VERSION ""

NS_ :

BS_:

BU_: FS Inverter BMS

BO_ 1317 IVT_Msg_Result_T: 8 Vector__XXX
 SG_ IVT_Result_T : 16|32@1- (1,0) [-2147483648|2147483647] "°C" Vector__XXX

BO_ 1313 IVT_Msg_Result_I: 8 Vector__XXX
 SG_ IVT_Result_I : 16|32@1- (0.001,0) [-2147483.648|2147483.647] "A" Vector__XXX

BO_ 1318 IVT_Msg_Result_W: 8 Vector__XXX
 SG_ IVT_Result_W : 16|32@1- (1,0) [-2147483648|2147483647] "W" Vector__XXX

BO_ 1316 IVT_Msg_Result_U3: 8 Vector__XXX
 SG_ IVT_Result_U3 : 16|32@1- (0.001,0) [-2147483.648|2147483.647] "V" Vector__XXX

BO_ 1315 IVT_Msg_Result_U2: 8 Vector__XXX
 SG_ IVT_Result_U2 : 16|32@1- (0.001,0) [-2147483.648|2147483.647] "V" Vector__XXX

BO_ 1314 IVT_Msg_Result_U1: 8 Vector__XXX
 SG_ IVT_Result_U1 : 16|32@1- (0.001,0) [-2147483.648|2147483.647] "V" Vector__XXX

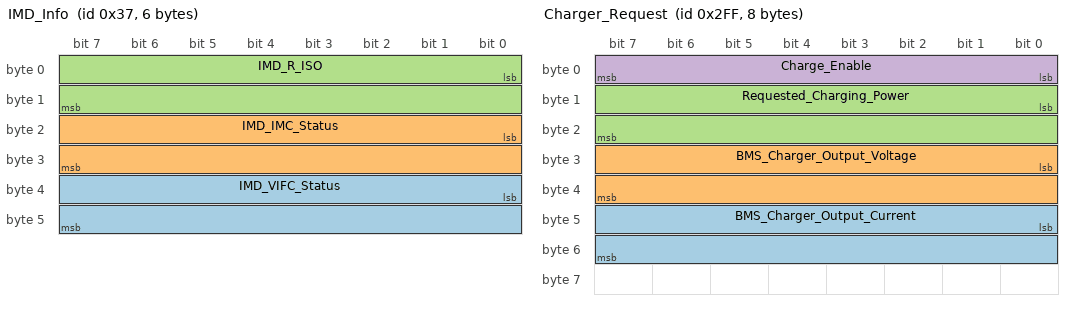
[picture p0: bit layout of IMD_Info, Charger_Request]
BO_ 55 IMD_Info: 6 Vector__XXX
 SG_ IMD_VIFC_Status : 32|16@1- (1,0) [0|0] "" Vector__XXX
 SG_ IMD_IMC_Status : 16|16@1- (1,0) [0|0] "" Vector__XXX
 SG_ IMD_R_ISO : 0|16@1- (1,0) [-32768|32767] "" Vector__XXX

BO_ 767 Charger_Request: 8 Vector__XXX
 SG_ BMS_Charger_Output_Current : 40|16@1+ (0.1,0) [0|6553.5] "A" Vector__XXX
 SG_ BMS_Charger_Output_Voltage : 24|16@1+ (0.1,0) [0|6553.5] "V" Vector__XXX
 SG_ Requested_Charging_Power : 8|16@1- (1,0) [-32768|32767] "" Vector__XXX
 SG_ Charge_Enable : 0|8@1- (1,0) [-128|127] "" Vector__XXX

BO_ 595 BMS_AvailCurrent: 8 Vector__XXX
 SG_ MaxDischarge : 16|16@1+ (0.1,0) [0|6553.5] "A" Vector__XXX
 SG_ MaxCharge : 0|16@1+ (0.1,0) [0|6553.5] "A" Vector__XXX

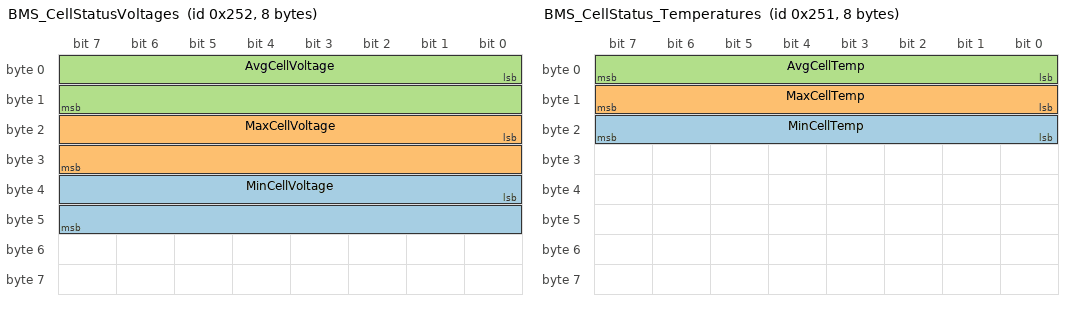
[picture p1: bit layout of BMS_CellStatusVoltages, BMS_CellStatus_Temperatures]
BO_ 594 BMS_CellStatusVoltages: 8 Vector__XXX
 SG_ MinCellVoltage : 32|16@1+ (0.1,0) [0|6553.5] "mV" Vector__XXX
 SG_ MaxCellVoltage : 16|16@1+ (0.1,0) [0|6553.5] "mV" Vector__XXX
 SG_ AvgCellVoltage : 0|16@1+ (0.1,0) [0|6553.5] "mV" Vector__XXX

BO_ 593 BMS_CellStatus_Temperatures: 8 Vector__XXX
 SG_ MinCellTemp : 16|8@1- (1,0) [-128|127] "degC" Vector__XXX
 SG_ MaxCellTemp : 8|8@1- (1,0) [-128|127] "degC" Vector__XXX
 SG_ AvgCellTemp : 0|8@1- (1,0) [-128|127] "degC" Vector__XXX

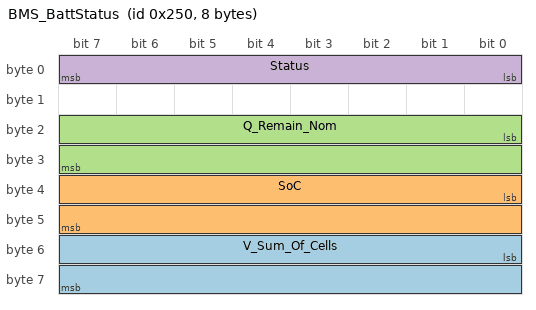
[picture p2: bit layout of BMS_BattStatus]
BO_ 592 BMS_BattStatus: 8 Vector__XXX
 SG_ V_Sum_Of_Cells : 48|16@1+ (0.1,0) [0|6553.5] "V" Vector__XXX
 SG_ SoC : 32|16@1- (0.01,0) [-327.68|327.67] "%" Vector__XXX
 SG_ Q_Remain_Nom : 16|16@1+ (0.1,0) [0|6553.5] "Ah" Vector__XXX
 SG_ Status : 0|8@1+ (1,0) [0|255] "" Vector__XXX

BA_DEF_  "BusType" STRING ;
BA_DEF_DEF_  "BusType" "CAN";
VAL_ 592 Status 4 "Error Mode" 3 "Active Mode" 2 "Await Active Mode" 1 "Ready Mode" 0 "Init Mode" ;
